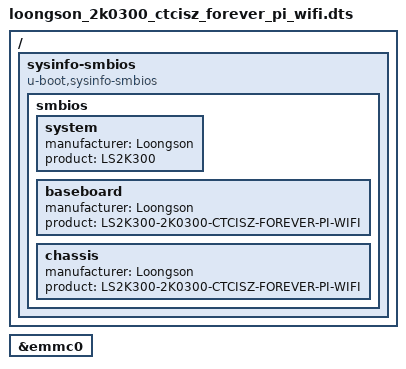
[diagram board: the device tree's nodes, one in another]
#include "loongson_2k0300_ctcisz_forever_pi.dtsi"
#include "ls2k300_ddr_samsung_512m.dtsi"
#include <dt-bindings/gpio/gpio.h>

/ {
	sysinfo-smbios {
		compatible = "u-boot,sysinfo-smbios";

		smbios {
			system {
				manufacturer = "Loongson";
				product = "LS2K300";
			};

			baseboard {
				manufacturer = "Loongson";
				product = "LS2K300-2K0300-CTCISZ-FOREVER-PI-WIFI";
			};

			chassis {
				manufacturer = "Loongson";
				product = "LS2K300-2K0300-CTCISZ-FOREVER-PI-WIFI";
			};
		};
	};
};

&emmc0 {
	status = "okay";
};
